VERSION "Aster Volt S powertrain / chassis CAN (500 kbit/s)"

NS_ :

BS_:

BU_: PT ESC BMS THERM HVAC

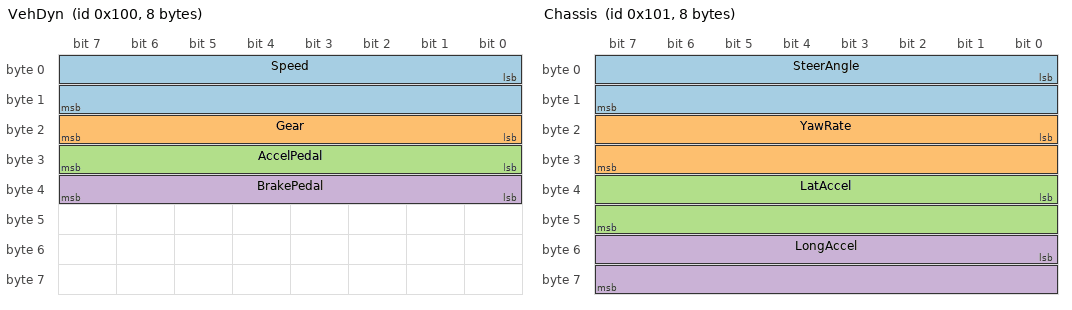
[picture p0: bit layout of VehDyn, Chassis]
BO_ 256 VehDyn: 8 PT
 SG_ Speed : 0|16@1+ (0.01,0) [0|655.35] "km/h" Vector__XXX
 SG_ Gear : 16|8@1+ (1,0) [0|8] "" Vector__XXX
 SG_ AccelPedal : 24|8@1+ (0.5,0) [0|100] "%" Vector__XXX
 SG_ BrakePedal : 32|8@1+ (0.5,0) [0|100] "%" Vector__XXX

BO_ 257 Chassis: 8 ESC
 SG_ SteerAngle : 0|16@1- (0.1,0) [-780|780] "deg" Vector__XXX
 SG_ YawRate : 16|16@1- (0.01,0) [-120|120] "deg/s" Vector__XXX
 SG_ LatAccel : 32|16@1- (0.001,0) [-30|30] "m/s2" Vector__XXX
 SG_ LongAccel : 48|16@1- (0.001,0) [-30|30] "m/s2" Vector__XXX

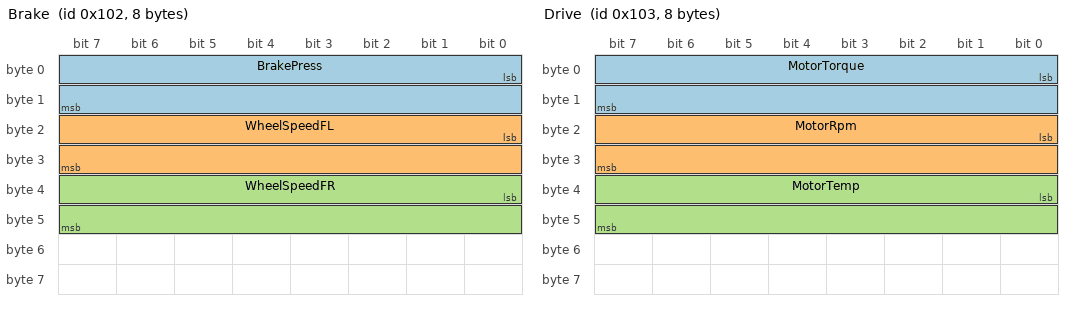
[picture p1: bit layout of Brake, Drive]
BO_ 258 Brake: 8 ESC
 SG_ BrakePress : 0|16@1+ (0.1,0) [0|200] "bar" Vector__XXX
 SG_ WheelSpeedFL : 16|16@1+ (0.01,0) [0|327.67] "km/h" Vector__XXX
 SG_ WheelSpeedFR : 32|16@1+ (0.01,0) [0|327.67] "km/h" Vector__XXX

BO_ 259 Drive: 8 PT
 SG_ MotorTorque : 0|16@1- (0.1,0) [-500|500] "Nm" Vector__XXX
 SG_ MotorRpm : 16|16@1- (1,0) [-2000|20000] "rpm" Vector__XXX
 SG_ MotorTemp : 32|16@1- (0.1,0) [-100|300] "degC" Vector__XXX

BO_ 528 Thermal: 8 THERM
 SG_ CoolantFlow : 0|16@1+ (0.1,0) [0|100] "L/min" Vector__XXX
 SG_ PumpRpm : 16|16@1+ (1,0) [0|8000] "rpm" Vector__XXX

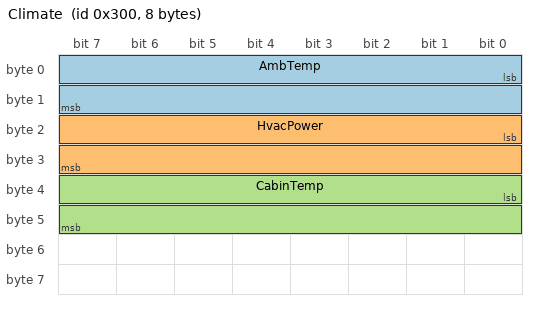
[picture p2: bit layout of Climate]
BO_ 768 Climate: 8 HVAC
 SG_ AmbTemp : 0|16@1- (0.1,0) [-100|100] "degC" Vector__XXX
 SG_ HvacPower : 16|16@1+ (10,0) [0|10000] "W" Vector__XXX
 SG_ CabinTemp : 32|16@1- (0.1,0) [-100|100] "degC" Vector__XXX
